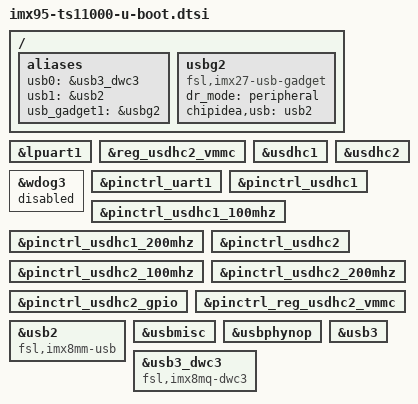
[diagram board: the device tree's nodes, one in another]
// SPDX-License-Identifier: GPL-2.0+
/*
 * Copyright 2025 NXP
 */

#include "imx95-u-boot.dtsi"
#include "imx95-ts11000-local.dtsi"

/ {
	aliases {
		usb0 = &usb3_dwc3;
		usb1 = &usb2;
		usb_gadget1 = &usbg2;
	};

	usbg2: usbg2 {
		compatible = "fsl,imx27-usb-gadget";
		dr_mode = "peripheral";
		chipidea,usb = <&usb2>;
		bootph-pre-ram;
		status = "okay";
	};
};

&lpuart1 {
	bootph-pre-ram;
};

&reg_usdhc2_vmmc {
	bootph-pre-ram;
};

&usdhc1 {
	bootph-pre-ram;
};

&usdhc2 {
	bootph-pre-ram;
};

&wdog3 {
	status = "disabled";
};

&pinctrl_uart1 {
	bootph-pre-ram;
};

&pinctrl_usdhc1 {
	bootph-pre-ram;
};

&pinctrl_usdhc1_100mhz {
	bootph-pre-ram;
};

&pinctrl_usdhc1_200mhz {
	bootph-pre-ram;
};

&pinctrl_usdhc2 {
	bootph-pre-ram;
};

&pinctrl_usdhc2_100mhz {
	bootph-pre-ram;
};

&pinctrl_usdhc2_200mhz {
	bootph-pre-ram;
};

&pinctrl_usdhc2_gpio {
	bootph-pre-ram;
};

&pinctrl_reg_usdhc2_vmmc {
	bootph-pre-ram;
};

&usb2 {
	compatible = "fsl,imx8mm-usb", "fsl,imx7d-usb";
	/delete-property/power-domains;
	bootph-pre-ram;
};

&usbmisc {
	bootph-pre-ram;
};

&usbphynop {
	bootph-pre-ram;
};

&usb3 {
	/delete-property/power-domains;
};

&usb3_dwc3 {
	compatible = "fsl,imx8mq-dwc3", "snps,dwc3";
};
